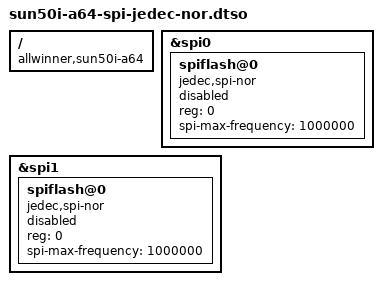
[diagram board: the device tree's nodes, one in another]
/dts-v1/;
/plugin/;

/ {
	compatible = "allwinner,sun50i-a64";

	fragment@0 {
		target = <&spi0>;
		__overlay__ {
			#address-cells = <1>;
			#size-cells = <0>;
			spiflash@0 {
				compatible = "jedec,spi-nor";
				reg = <0>;
				spi-max-frequency = <1000000>;
				status = "disabled";
			};
		};
	};

	fragment@1 {
		target = <&spi1>;
		__overlay__ {
			#address-cells = <1>;
			#size-cells = <0>;
			spiflash@0 {
				compatible = "jedec,spi-nor";
				reg = <0>;
				spi-max-frequency = <1000000>;
				status = "disabled";
			};
		};
	};
};
